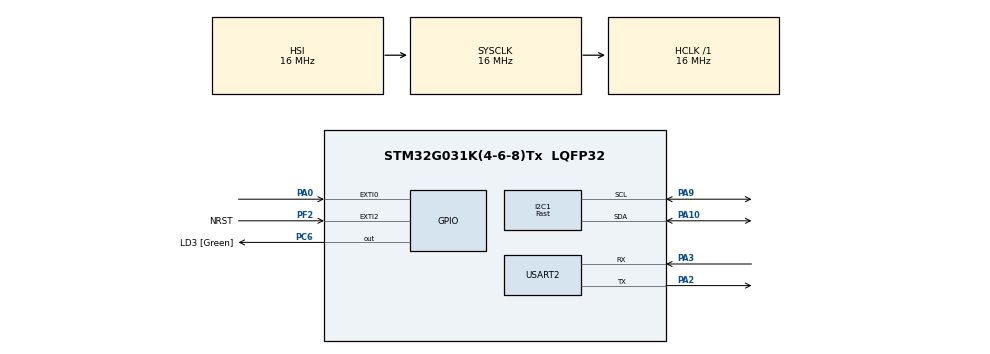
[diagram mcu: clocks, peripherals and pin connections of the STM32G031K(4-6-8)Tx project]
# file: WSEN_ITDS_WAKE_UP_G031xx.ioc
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I2C1.I2C_Speed_Mode=I2C_Fast
I2C1.Timing=0x0010061A
Mcu.Family=STM32G0
Mcu.Name=STM32G031K(4-6-8)Tx
Mcu.Package=LQFP32
NVIC.EXTI0_1_IRQn=true\:0\:0\:false\:false\:true\:true\:true
PA0.GPIO_ModeDefaultEXTI=GPIO_MODE_IT_RISING
PA0.Signal=GPXTI0
PA10.GPIO_Pu=GPIO_PULLUP
PA10.GPIO_Speed=GPIO_SPEED_FREQ_VERY_HIGH
PA10.Mode=I2C
PA10.Signal=I2C1_SDA
PA13.Mode=Serial_Wire
PA13.Signal=SYS_SWDIO
PA14-BOOT0.Mode=Serial_Wire
PA14-BOOT0.Signal=SYS_SWCLK
PA2.Mode=Asynchronous
PA2.Signal=USART2_TX
PA3.Mode=Asynchronous
PA3.Signal=USART2_RX
PA9.GPIO_Pu=GPIO_PULLUP
PA9.GPIO_Speed=GPIO_SPEED_FREQ_VERY_HIGH
PA9.Mode=I2C
PA9.Signal=I2C1_SCL
PC6.GPIO_Label=LD3 [Green]
PC6.Signal=GPIO_Output
PF2\ -\ NRST.GPIO_Label=NRST
PF2\ -\ NRST.Signal=GPXTI2
ProjectManager.HeapSize=0x200
ProjectManager.StackSize=0x400
ProjectManager.TargetToolchain=STM32CubeIDE
RCC.AHBFreq_Value=16000000
RCC.CortexFreq_Value=16000000
RCC.EXTERNAL_CLOCK_VALUE=12288000
RCC.HCLKFreq_Value=16000000
RCC.HSE_VALUE=8000000
RCC.HSI_VALUE=16000000
RCC.LSE_VALUE=32768
RCC.SYSCLKFreq_VALUE=16000000
RCC.VCOOutputFreq_Value=128000000
USART2.VirtualMode-Asynchronous=VM_ASYNC
board=custom

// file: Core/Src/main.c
/* USER CODE BEGIN Header */
/*
 ***************************************************************************************************
 * This file is part of Sensors SDK:
 * https://www.we-online.com/sensors, https://github.com/WurthElektronik/Sensors-SDK_STM32
 *
 * THE SOFTWARE INCLUDING THE SOURCE CODE IS PROVIDED “AS IS”. YOU ACKNOWLEDGE THAT WÜRTH ELEKTRONIK
 * EISOS MAKES NO REPRESENTATIONS AND WARRANTIES OF ANY KIND RELATED TO, BUT NOT LIMITED
 * TO THE NON-INFRINGEMENT OF THIRD PARTIES’ INTELLECTUAL PROPERTY RIGHTS OR THE
 * MERCHANTABILITY OR FITNESS FOR YOUR INTENDED PURPOSE OR USAGE. WÜRTH ELEKTRONIK EISOS DOES NOT
 * WARRANT OR REPRESENT THAT ANY LICENSE, EITHER EXPRESS OR IMPLIED, IS GRANTED UNDER ANY PATENT
 * RIGHT, COPYRIGHT, MASK WORK RIGHT, OR OTHER INTELLECTUAL PROPERTY RIGHT RELATING TO ANY
 * COMBINATION, MACHINE, OR PROCESS IN WHICH THE PRODUCT IS USED. INFORMATION PUBLISHED BY
 * WÜRTH ELEKTRONIK EISOS REGARDING THIRD-PARTY PRODUCTS OR SERVICES DOES NOT CONSTITUTE A LICENSE
 * FROM WÜRTH ELEKTRONIK EISOS TO USE SUCH PRODUCTS OR SERVICES OR A WARRANTY OR ENDORSEMENT
 * THEREOF
 *
 * THIS SOURCE CODE IS PROTECTED BY A LICENSE.
 * FOR MORE INFORMATION PLEASE CAREFULLY READ THE LICENSE AGREEMENT FILE (license_terms_wsen_sdk.pdf)
 * LOCATED IN THE ROOT DIRECTORY OF THIS DRIVER PACKAGE.
 *
 * COPYRIGHT (c) 2022 Würth Elektronik eiSos GmbH & Co. KG
 *
 ***************************************************************************************************
 */
/* USER CODE END Header */
#include "main.h"
#include "i2c.h"
#include "usart.h"
#include "gpio.h"

/* USER CODE BEGIN Includes */

#include "examples/WSEN_ITDS_WAKE_UP/WSEN_ITDS_WAKE_UP_EXAMPLE.h"

/* USER CODE END Includes */

void SystemClock_Config(void);

int main(void)
{

  /* MCU Configuration--------------------------------------------------------*/

  /* Reset of all peripherals, Initializes the Flash interface and the Systick. */
  HAL_Init();

  /* Configure the system clock */
  SystemClock_Config();

  /* Initialize all configured peripherals */
  MX_GPIO_Init();
  MX_I2C1_Init();
  MX_USART2_UART_Init();
  /* USER CODE BEGIN 2 */

  WE_itdsWakeUpExampleInit();

  /* USER CODE END 2 */

  /* Infinite loop */
  while (1)
  {

    /* USER CODE BEGIN 3 */

    WE_itdsWakeUpExampleLoop();
  }
  /* USER CODE END 3 */
}

void SystemClock_Config(void)
{
  RCC_OscInitTypeDef RCC_OscInitStruct = {0};
  RCC_ClkInitTypeDef RCC_ClkInitStruct = {0};
  RCC_PeriphCLKInitTypeDef PeriphClkInit = {0};

  /** Configure the main internal regulator output voltage
  */
  HAL_PWREx_ControlVoltageScaling(PWR_REGULATOR_VOLTAGE_SCALE1);
  /** Initializes the RCC Oscillators according to the specified parameters
  * in the RCC_OscInitTypeDef structure.
  */
  RCC_OscInitStruct.OscillatorType = RCC_OSCILLATORTYPE_HSI;
  RCC_OscInitStruct.HSIState = RCC_HSI_ON;
  RCC_OscInitStruct.HSIDiv = RCC_HSI_DIV1;
  RCC_OscInitStruct.HSICalibrationValue = RCC_HSICALIBRATION_DEFAULT;
  RCC_OscInitStruct.PLL.PLLState = RCC_PLL_NONE;
  if (HAL_RCC_OscConfig(&RCC_OscInitStruct) != HAL_OK)
  {
    Error_Handler();
  }
  /** Initializes the CPU, AHB and APB buses clocks
  */
  RCC_ClkInitStruct.ClockType = RCC_CLOCKTYPE_HCLK|RCC_CLOCKTYPE_SYSCLK
                              |RCC_CLOCKTYPE_PCLK1;
  RCC_ClkInitStruct.SYSCLKSource = RCC_SYSCLKSOURCE_HSI;
  RCC_ClkInitStruct.AHBCLKDivider = RCC_SYSCLK_DIV1;
  RCC_ClkInitStruct.APB1CLKDivider = RCC_HCLK_DIV1;

  if (HAL_RCC_ClockConfig(&RCC_ClkInitStruct, FLASH_LATENCY_0) != HAL_OK)
  {
    Error_Handler();
  }
  /** Initializes the peripherals clocks
  */
  PeriphClkInit.PeriphClockSelection = RCC_PERIPHCLK_I2C1;
  PeriphClkInit.I2c1ClockSelection = RCC_I2C1CLKSOURCE_PCLK1;
  if (HAL_RCCEx_PeriphCLKConfig(&PeriphClkInit) != HAL_OK)
  {
    Error_Handler();
  }
}

void Error_Handler(void)
{
  __disable_irq();
  while (1)
  {
  }
}

/************************ (C) COPYRIGHT STMicroelectronics *****END OF FILE****/
